# USB0_DEBUG_TRACE_MMR_TRACE_VBUSP_USB2SS_DEBUG_TRACE register map
Vendor: Texas Instruments
Peripheral module from a debugger description file (folder am62P).
Registers are 32-bit, read-write, reset 0x0 unless marked. A register's access mark holds for its fields unless they carry their own. Offsets are as the file gives them; lines under a group give offsets from that group; [hi:lo] are bit positions; {n}, {i} and the like mark numbered series; 'fields as' and 'values as' point back to an identical list; <NAME> marks a mode.

## USB0_DEBUG_TRACE_MMR_TRACE_VBUSP_USB2SS_DEBUG_TRACE
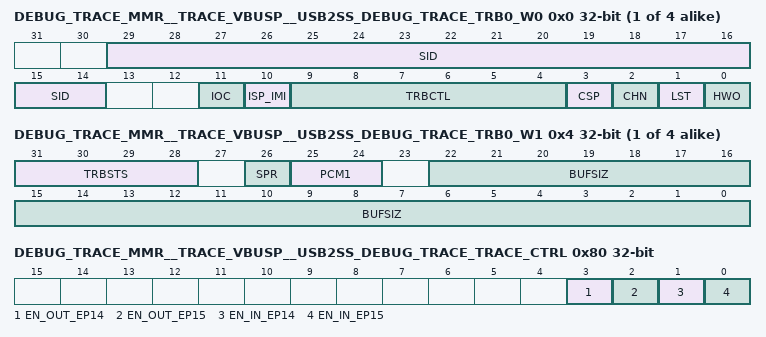
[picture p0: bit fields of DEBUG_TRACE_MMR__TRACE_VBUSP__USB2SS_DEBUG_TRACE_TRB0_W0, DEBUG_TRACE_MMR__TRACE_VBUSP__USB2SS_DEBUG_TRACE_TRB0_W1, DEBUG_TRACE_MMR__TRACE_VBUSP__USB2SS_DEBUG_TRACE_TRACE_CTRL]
{0x0+0x10*i} DEBUG_TRACE_MMR__TRACE_VBUSP__USB2SS_DEBUG_TRACE_TRB{i}_W0 (i=0..3) — TRB{i} Word 0. Please refer to Controller programming guide for more details on these fields.
  [29:14] SID — Stream ID / SOF Number
  [11] IOC — Interrupt on Complete
  [10] ISP_IMI — Interrupt on Short Packet / Interrupt on Missed ISOC
  [9:4] TRBCTL — Indicates the type of TRB
  [3] CSP — Continue on Short Packet
  [2] CHN — Chain buffers
  [1] LST — Indicates this is the last TRB in a list
  [0] HWO — Hardware Owner of Descriptor
{0x4+0x10*i} DEBUG_TRACE_MMR__TRACE_VBUSP__USB2SS_DEBUG_TRACE_TRB{i}_W1 (i=0..3) — TRB{i} Word 1. Please refer to Controller programming guide for more details on these fields.
  [31:28] TRBSTS — Packet Count M1
  [26] SPR — Short packet received/Reserved bits
  [25:24] PCM1 — Packet Count M1
  [22:0] BUFSIZ — Buffer Size
{0x8+0x10*i} DEBUG_TRACE_MMR__TRACE_VBUSP__USB2SS_DEBUG_TRACE_TRB{i}_W2 (i=0..3) — TRB{i} Word 2. Please refer to Controller programming guide for more details on these fields.
  [31:0] BPTRH — Buffer Pointer High
{0xC+0x10*i} DEBUG_TRACE_MMR__TRACE_VBUSP__USB2SS_DEBUG_TRACE_TRB{i}_W3 (i=0..3) — TRB{i} Word 3. Please refer to Controller programming guide for more details on these fields.
  [31:0] BPTRL — Buffer Pointer Low
0x80 DEBUG_TRACE_MMR__TRACE_VBUSP__USB2SS_DEBUG_TRACE_TRACE_CTRL access per field — Debug trace control register
  [3] EN_OUT_EP14 rw — Debug trace enable for OUT Endpoint 14
  [2] EN_OUT_EP15 rw — Debug trace enable for OUT Endpoint 15
  [1] EN_IN_EP14 rw — Debug trace enable for IN Endpoint 14
  [0] EN_IN_EP15 rw — Debug trace enable for IN Endpoint 15
